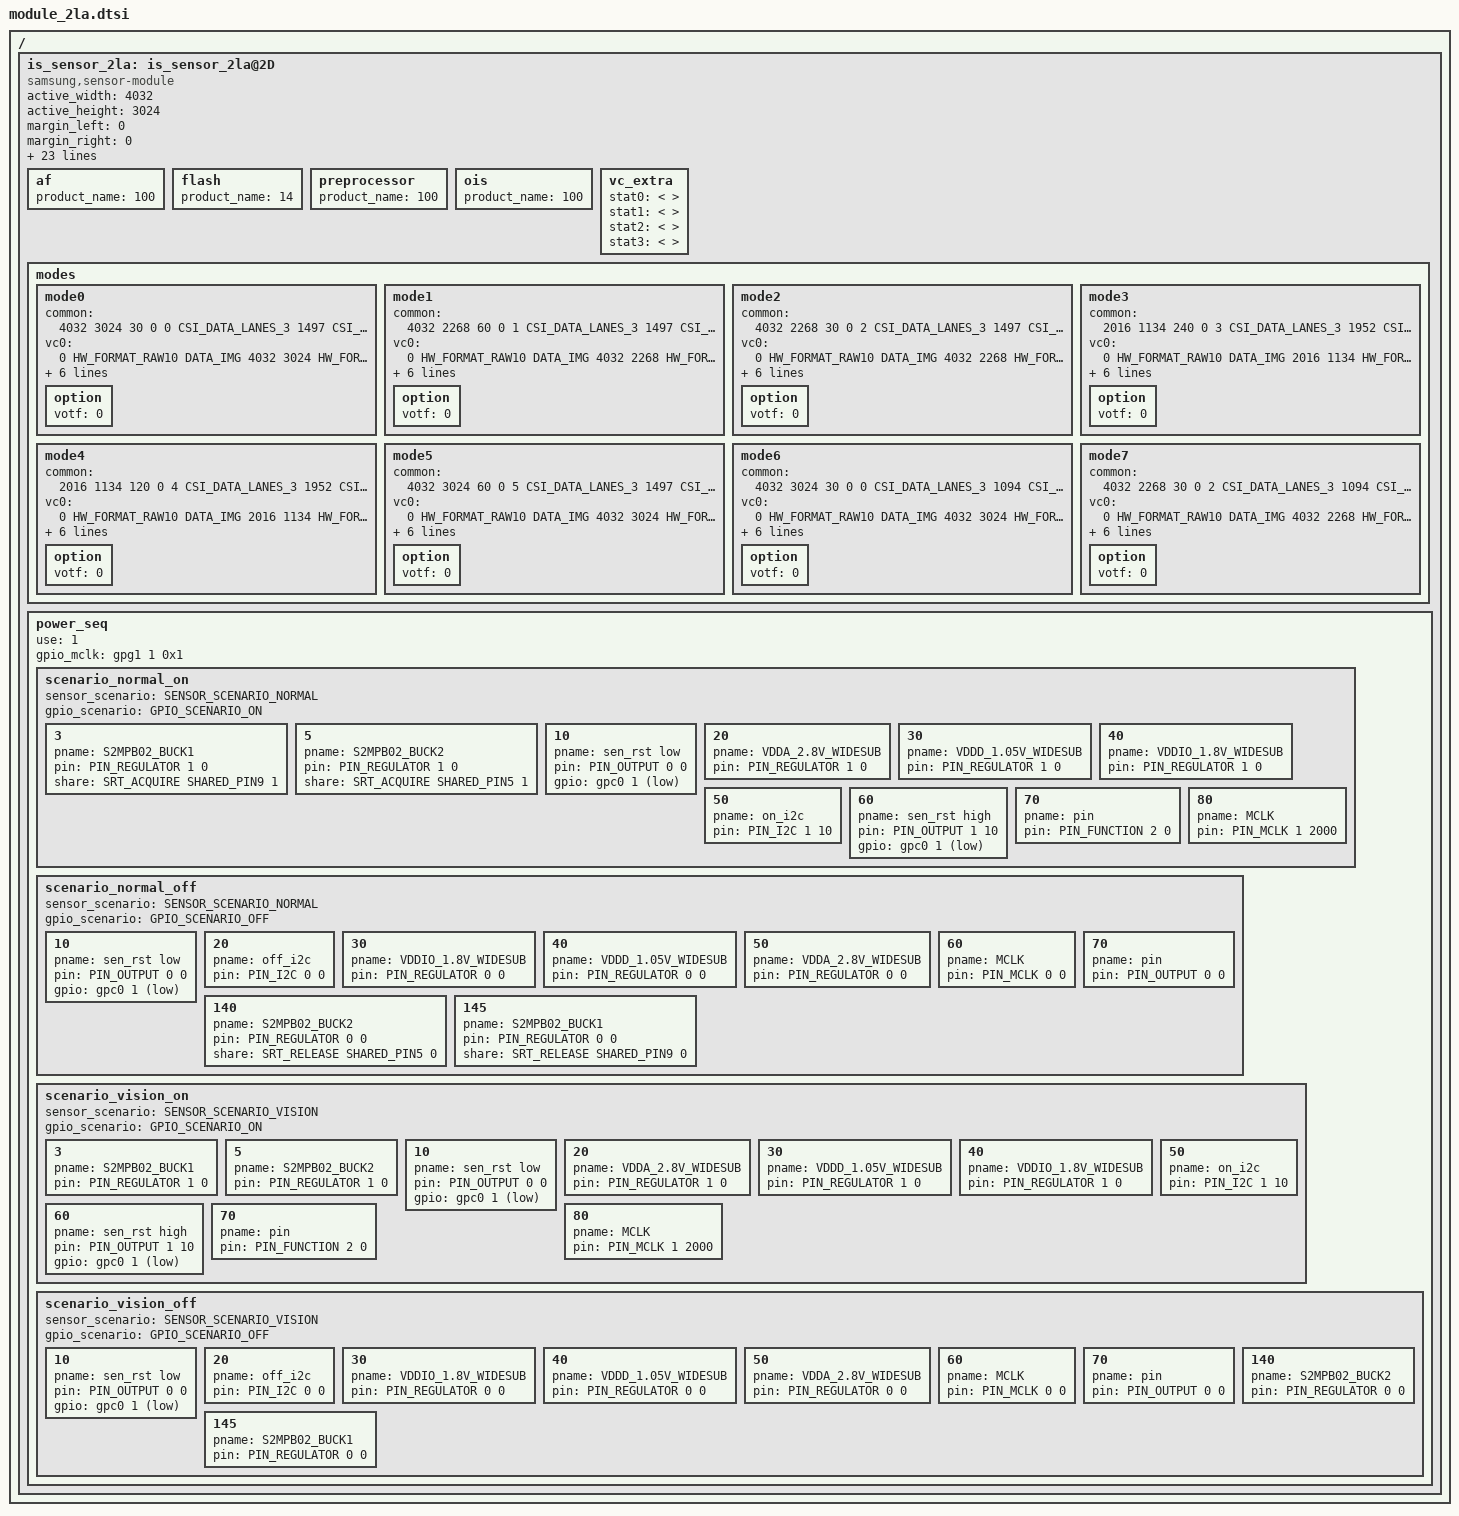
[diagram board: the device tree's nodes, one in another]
/*
 * SAMSUNG EXYNOSxxxx board camera device tree source
 *
 * Copyright (c) 2019 Samsung Electronics Co., Ltd.
 *		http://www.samsung.com
 *
 * This program is free software; you can redistribute it and/or modify
 * it under the terms of the GNU General Public License version 2 as
 * published by the Free Software Foundation.
 */

#include <dt-bindings/camera/exynos_is_dt.h>

/ {
	fragment@camera {
		target-path = "/";
		__overlay__ {
			is_sensor_2la: is_sensor_2la@2D {
				compatible = "samsung,sensor-module";

				/* common */
				active_width = <4032>;
				active_height = <3024>;
				margin_left = <0>;
				margin_right = <0>;
				margin_top = <0>;
				margin_bottom = <0>;
				max_framerate = <240>;
				bitwidth = <10>;
				use_retention_mode = <SENSOR_RETENTION_UNSUPPORTED>;
				sensor_maker = "SLSI";
				sensor_name = "2LA";
				setfile_name = "setfile_2la.bin";

				status = "okay";

				/* board */
				pinctrl-names = "pin0", "pin1", "pin2", "release";
				pinctrl-0 = <>;
				pinctrl-1 = <&sensor_mclk1_out>;
				pinctrl-2 = <&sensor_mclk1_fn>;
				pinctrl-3 = <>;

				position = <4>; /* Rear:0. Front:1, Tele:2 */
				id = <4>; /* is_sensor id */
				mclk_ch = <1>;
				mclk_freq = <19200>;
				sensor_i2c_ch = <3>; /* SENSOR_CONTROL_I2C3 */

				/* vendor */
				rom_type = <2>; /* ROM_TYPE_EEPROM */
				rom_id = <2>;
				rom_cal_index = <0>;
				rom_dualcal_id = <0>;
				rom_dualcal_index = <0>;

				af {
					product_name = <100>; /* NOTHING */
				};

				flash {
					product_name = <14>; /* S2MU106 */
				};

				preprocessor {
					product_name = <100>; /* NOTHING */
				};

				ois {
					product_name = <100>; /* NOTHING */
				};

				vc_extra {
					/* ex) statX = <stat_type, sensor_mode, max_width, max_height, max_element> */
					stat0 = </* not avaliable */>;	/* VC_BUF_DATA_TYPE_SENSOR_STAT1 */
					stat1 = </* not avaliable */>;	/* VC_BUF_DATA_TYPE_GENERAL_STAT1 */
					stat2 = </* not avaliable */>;	/* VC_BUF_DATA_TYPE_SENSOR_STAT2 */
					stat3 = </* not avaliable */>;	/* VC_BUF_DATA_TYPE_GENERAL_STAT2 */
				};

				/* sensor modes */
				modes {
						/* common = <width, height, fps, settle, mode, lane, speed, interleave, lrte, pd_mode> */
						/* vcX = <map, hwformat, width, height, hwformat, type, width, height> */
					mode0 {
						common = <4032 3024 30 0 0 CSI_DATA_LANES_3 1497 CSI_MODE_VC_ONLY LRTE_DISABLE PD_NONE>;
						vc0 = </* in */ 0 HW_FORMAT_RAW10 DATA_IMG 4032 3024	/* out */ HW_FORMAT_RAW10 VC_NOTHING 4032 3024>;
						vc1 = </* in */ 1 HW_FORMAT_UNKNOWN DATA_NONE 0 0		/* out */ HW_FORMAT_UNKNOWN VC_NOTHING 0 0>;
						vc2 = </* in */ 2 HW_FORMAT_UNKNOWN DATA_NONE 0 0		/* out */ HW_FORMAT_UNKNOWN VC_NOTHING 0 0>;
						vc3 = </* in */ 3 HW_FORMAT_UNKNOWN DATA_NONE 0 0		/* out */ HW_FORMAT_UNKNOWN VC_NOTHING 0 0>;
						option { votf = <0>; };
					};
					mode1 {
						common = <4032 2268 60 0 1 CSI_DATA_LANES_3 1497 CSI_MODE_VC_ONLY LRTE_DISABLE PD_NONE>;
						vc0 = </* in */ 0 HW_FORMAT_RAW10 DATA_IMG 4032 2268	/* out */ HW_FORMAT_RAW10 VC_NOTHING 4032 2268>;
						vc1 = </* in */ 1 HW_FORMAT_UNKNOWN DATA_NONE 0 0		/* out */ HW_FORMAT_UNKNOWN VC_NOTHING 0 0>;
						vc2 = </* in */ 2 HW_FORMAT_UNKNOWN DATA_NONE 0 0		/* out */ HW_FORMAT_UNKNOWN VC_NOTHING 0 0>;
						vc3 = </* in */ 3 HW_FORMAT_UNKNOWN DATA_NONE 0 0		/* out */ HW_FORMAT_UNKNOWN VC_NOTHING 0 0>;
						option { votf = <0>; };
					};
					mode2 {
						common = <4032 2268 30 0 2 CSI_DATA_LANES_3 1497 CSI_MODE_VC_ONLY LRTE_DISABLE PD_NONE>;
						vc0 = </* in */ 0 HW_FORMAT_RAW10 DATA_IMG 4032 2268	/* out */ HW_FORMAT_RAW10 VC_NOTHING 4032 2268>;
						vc1 = </* in */ 1 HW_FORMAT_UNKNOWN DATA_NONE 0 0		/* out */ HW_FORMAT_UNKNOWN VC_NOTHING 0 0>;
						vc2 = </* in */ 2 HW_FORMAT_UNKNOWN DATA_NONE 0 0		/* out */ HW_FORMAT_UNKNOWN VC_NOTHING 0 0>;
						vc3 = </* in */ 3 HW_FORMAT_UNKNOWN DATA_NONE 0 0		/* out */ HW_FORMAT_UNKNOWN VC_NOTHING 0 0>;
						option { votf = <0>; };
					};
					mode3 {
						common = <2016 1134 240 0 3 CSI_DATA_LANES_3 1952 CSI_MODE_VC_ONLY LRTE_DISABLE PD_NONE>;
						vc0 = </* in */ 0 HW_FORMAT_RAW10 DATA_IMG 2016 1134	/* out */ HW_FORMAT_RAW10 VC_NOTHING 2016 1134>;
						vc1 = </* in */ 1 HW_FORMAT_UNKNOWN DATA_NONE 0 0		/* out */ HW_FORMAT_UNKNOWN VC_NOTHING 0 0>;
						vc2 = </* in */ 2 HW_FORMAT_UNKNOWN DATA_NONE 0 0		/* out */ HW_FORMAT_UNKNOWN VC_NOTHING 0 0>;
						vc3 = </* in */ 3 HW_FORMAT_UNKNOWN DATA_NONE 0 0		/* out */ HW_FORMAT_UNKNOWN VC_NOTHING 0 0>;
						option { votf = <0>; };
					};
					mode4 {
						common = <2016 1134 120 0 4 CSI_DATA_LANES_3 1952 CSI_MODE_VC_ONLY LRTE_DISABLE PD_NONE>;
						vc0 = </* in */ 0 HW_FORMAT_RAW10 DATA_IMG 2016 1134	/* out */ HW_FORMAT_RAW10 VC_NOTHING 2016 1134>;
						vc1 = </* in */ 1 HW_FORMAT_UNKNOWN DATA_NONE 0 0		/* out */ HW_FORMAT_UNKNOWN VC_NOTHING 0 0>;
						vc2 = </* in */ 2 HW_FORMAT_UNKNOWN DATA_NONE 0 0		/* out */ HW_FORMAT_UNKNOWN VC_NOTHING 0 0>;
						vc3 = </* in */ 3 HW_FORMAT_UNKNOWN DATA_NONE 0 0		/* out */ HW_FORMAT_UNKNOWN VC_NOTHING 0 0>;
						option { votf = <0>; };
					};
					mode5 {
						common = <4032 3024 60 0 5 CSI_DATA_LANES_3 1497 CSI_MODE_VC_ONLY LRTE_DISABLE PD_NONE>;
						vc0 = </* in */ 0 HW_FORMAT_RAW10 DATA_IMG 4032 3024	/* out */ HW_FORMAT_RAW10 VC_NOTHING 4032 3024>;
						vc1 = </* in */ 1 HW_FORMAT_UNKNOWN DATA_NONE 0 0		/* out */ HW_FORMAT_UNKNOWN VC_NOTHING 0 0>;
						vc2 = </* in */ 2 HW_FORMAT_UNKNOWN DATA_NONE 0 0		/* out */ HW_FORMAT_UNKNOWN VC_NOTHING 0 0>;
						vc3 = </* in */ 3 HW_FORMAT_UNKNOWN DATA_NONE 0 0		/* out */ HW_FORMAT_UNKNOWN VC_NOTHING 0 0>;
						option { votf = <0>; };
					};
					mode6 {
						common = <4032 3024 30 0 0 CSI_DATA_LANES_3 1094 CSI_MODE_VC_ONLY LRTE_DISABLE PD_NONE EX_LIVEFOCUS>;
						vc0 = </* in */ 0 HW_FORMAT_RAW10 DATA_IMG 4032 3024	/* out */ HW_FORMAT_RAW10 VC_NOTHING 4032 3024>;
						vc1 = </* in */ 1 HW_FORMAT_UNKNOWN DATA_NONE 0 0		/* out */ HW_FORMAT_UNKNOWN VC_NOTHING 0 0>;
						vc2 = </* in */ 2 HW_FORMAT_UNKNOWN DATA_NONE 0 0		/* out */ HW_FORMAT_UNKNOWN VC_NOTHING 0 0>;
						vc3 = </* in */ 3 HW_FORMAT_UNKNOWN DATA_NONE 0 0		/* out */ HW_FORMAT_UNKNOWN VC_NOTHING 0 0>;
						option { votf = <0>; };
					};
					mode7 {
						common = <4032 2268 30 0 2 CSI_DATA_LANES_3 1094 CSI_MODE_VC_ONLY LRTE_DISABLE PD_NONE EX_LIVEFOCUS>;
						vc0 = </* in */ 0 HW_FORMAT_RAW10 DATA_IMG 4032 2268	/* out */ HW_FORMAT_RAW10 VC_NOTHING 4032 2268>;
						vc1 = </* in */ 1 HW_FORMAT_UNKNOWN DATA_NONE 0 0		/* out */ HW_FORMAT_UNKNOWN VC_NOTHING 0 0>;
						vc2 = </* in */ 2 HW_FORMAT_UNKNOWN DATA_NONE 0 0		/* out */ HW_FORMAT_UNKNOWN VC_NOTHING 0 0>;
						vc3 = </* in */ 3 HW_FORMAT_UNKNOWN DATA_NONE 0 0		/* out */ HW_FORMAT_UNKNOWN VC_NOTHING 0 0>;
						option { votf = <0>; };
					};
				};

				power_seq {
					use = <1>;
					gpio_mclk = <&gpg1 1 0x1>;
					scenario_normal_on {
						sensor_scenario = <SENSOR_SCENARIO_NORMAL>;
						gpio_scenario = <GPIO_SCENARIO_ON>;

						/* A start node number should be over the 10 for reserved number 0~9. */
						/* pname = "name"; pin = <act value dealy voltage>; gpio = <gpx# # 0x1>; */
						3 { pname = "S2MPB02_BUCK1"; pin = <PIN_REGULATOR 1 0>; share = <SRT_ACQUIRE SHARED_PIN9 1>; };
						5 { pname = "S2MPB02_BUCK2"; pin = <PIN_REGULATOR 1 0>; share = <SRT_ACQUIRE SHARED_PIN5 1>; };
						10 { pname = "sen_rst low"; pin = <PIN_OUTPUT 0 0>; gpio = <&gpc0 1 0x1>; };
						20 { pname = "VDDA_2.8V_WIDESUB"; pin = <PIN_REGULATOR 1 0>; };
						30 { pname = "VDDD_1.05V_WIDESUB"; pin = <PIN_REGULATOR 1 0>; };
						40 { pname = "VDDIO_1.8V_WIDESUB"; pin = <PIN_REGULATOR 1 0>; };
						50 { pname = "on_i2c"; pin = <PIN_I2C 1 10>; };
						60 { pname = "sen_rst high"; pin = <PIN_OUTPUT 1 10>; gpio = <&gpc0 1 0x1>; };
						70 { pname = "pin"; pin = <PIN_FUNCTION 2 0>; };
						80 { pname = "MCLK"; pin = <PIN_MCLK 1 2000>; };
					};

					scenario_normal_off {
						sensor_scenario = <SENSOR_SCENARIO_NORMAL>;
						gpio_scenario = <GPIO_SCENARIO_OFF>;

						/* A start node number should be over the 10 for reserved number 0~9. */
						/* pname = "name"; pin = <act value dealy voltage>; gpio = <gpx# # 0x1>; */
						10 { pname = "sen_rst low"; pin = <PIN_OUTPUT 0 0>; gpio = <&gpc0 1 0x1>; };
						20 { pname = "off_i2c"; pin = <PIN_I2C 0 0>; };
						30 { pname = "VDDIO_1.8V_WIDESUB"; pin = <PIN_REGULATOR 0 0>; };
						40 { pname = "VDDD_1.05V_WIDESUB"; pin = <PIN_REGULATOR 0 0>; };
						50 { pname = "VDDA_2.8V_WIDESUB"; pin = <PIN_REGULATOR 0 0>; };
						60 { pname = "MCLK"; pin = <PIN_MCLK 0 0>; };
						70 { pname = "pin"; pin = <PIN_OUTPUT 0 0>; };
						140 { pname = "S2MPB02_BUCK2"; pin = <PIN_REGULATOR 0 0>; share = <SRT_RELEASE SHARED_PIN5 0>; };
						145 { pname = "S2MPB02_BUCK1"; pin = <PIN_REGULATOR 0 0>; share = <SRT_RELEASE SHARED_PIN9 0>; };
					};

					scenario_vision_on {
						sensor_scenario = <SENSOR_SCENARIO_VISION>;
						gpio_scenario = <GPIO_SCENARIO_ON>;

						/* A start node number should be over the 10 for reserved number 0~9. */
						/* pname = "name"; pin = <act value dealy voltage>; gpio = <gpx# # 0x1>; */
						3 { pname = "S2MPB02_BUCK1"; pin = <PIN_REGULATOR 1 0>; };
						5 { pname = "S2MPB02_BUCK2"; pin = <PIN_REGULATOR 1 0>; };
						10 { pname = "sen_rst low"; pin = <PIN_OUTPUT 0 0>; gpio = <&gpc0 1 0x1>; };
						20 { pname = "VDDA_2.8V_WIDESUB"; pin = <PIN_REGULATOR 1 0>; };
						30 { pname = "VDDD_1.05V_WIDESUB"; pin = <PIN_REGULATOR 1 0>; };
						40 { pname = "VDDIO_1.8V_WIDESUB"; pin = <PIN_REGULATOR 1 0>; };
						50 { pname = "on_i2c"; pin = <PIN_I2C 1 10>; };
						60 { pname = "sen_rst high"; pin = <PIN_OUTPUT 1 10>; gpio = <&gpc0 1 0x1>; };
						70 { pname = "pin"; pin = <PIN_FUNCTION 2 0>; };
						80 { pname = "MCLK"; pin = <PIN_MCLK 1 2000>; };
					};

					scenario_vision_off {
						sensor_scenario = <SENSOR_SCENARIO_VISION>;
						gpio_scenario = <GPIO_SCENARIO_OFF>;

						/* A start node number should be over the 10 for reserved number 0~9. */
						/* pname = "name"; pin = <act value dealy voltage>; gpio = <gpx# # 0x1>; */
						10 { pname = "sen_rst low"; pin = <PIN_OUTPUT 0 0>; gpio = <&gpc0 1 0x1>; };
						20 { pname = "off_i2c"; pin = <PIN_I2C 0 0>; };
						30 { pname = "VDDIO_1.8V_WIDESUB"; pin = <PIN_REGULATOR 0 0>; };
						40 { pname = "VDDD_1.05V_WIDESUB"; pin = <PIN_REGULATOR 0 0>; };
						50 { pname = "VDDA_2.8V_WIDESUB"; pin = <PIN_REGULATOR 0 0>; };
						60 { pname = "MCLK"; pin = <PIN_MCLK 0 0>; };
						70 { pname = "pin"; pin = <PIN_OUTPUT 0 0>; };
						140 { pname = "S2MPB02_BUCK2"; pin = <PIN_REGULATOR 0 0>; };
						145 { pname = "S2MPB02_BUCK1"; pin = <PIN_REGULATOR 0 0>; };
					};
				};
			};
		}; /* end of __overlay__ */
	}; /* end of fragment */
}; /* end of root */
